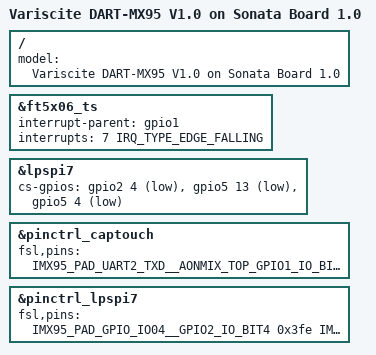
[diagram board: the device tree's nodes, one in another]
// SPDX-License-Identifier: (GPL-2.0+ OR MIT)
/*
 * Copyright 2023 NXP
 * Copyright 2024-2025 Variscite Ltd.
 */

#include "imx95-var-dart-sonata.dts"

/ {
	model = "Variscite DART-MX95 V1.0 on Sonata Board 1.0";
};

&ft5x06_ts {
	interrupt-parent = <&gpio1>;
	interrupts = <7 IRQ_TYPE_EDGE_FALLING>;
};

&lpspi7 {
	cs-gpios = <&gpio2 4 GPIO_ACTIVE_LOW>,
		   <&gpio5 13 GPIO_ACTIVE_LOW>,
		   <&gpio5 4 GPIO_ACTIVE_LOW>;
};

&pinctrl_captouch {
	fsl,pins = <
		IMX95_PAD_UART2_TXD__AONMIX_TOP_GPIO1_IO_BIT7           0x31e
	>;
};

&pinctrl_lpspi7 {
	fsl,pins = <
		IMX95_PAD_GPIO_IO04__GPIO2_IO_BIT4				0x3fe		/* j16.4 ADS7846 */
		IMX95_PAD_GPIO_IO33__GPIO5_IO_BIT13				0x3fe		/* j14.4 MCP2518FDT */
		IMX95_PAD_XSPI1_DATA4__GPIO5_IO_BIT4				0x3fe		/* j25.2 spidev */
		IMX95_PAD_GPIO_IO05__LPSPI7_SIN					0x3fe
		IMX95_PAD_GPIO_IO06__LPSPI7_SOUT				0x3fe
		IMX95_PAD_GPIO_IO07__LPSPI7_SCK					0x3fe
	>;
};
